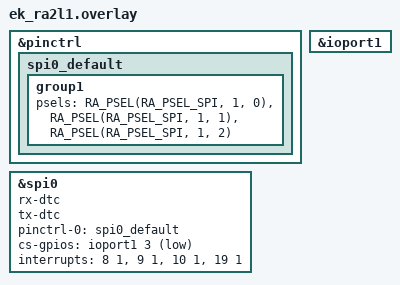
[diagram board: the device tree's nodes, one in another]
/*
 * Copyright (c) 2024 Renesas Electronics Corporation
 * SPDX-License-Identifier: Apache-2.0
 */

#define SPI_LOOPBACK_SLOW_HZ 2000000
#define SPI_LOOPBACK_FAST_HZ 3000000

&pinctrl {
	spi0_default: spi0_default {
		group1 {
			/* MISO MOSI RSPCK */
			psels = <RA_PSEL(RA_PSEL_SPI, 1, 0)>,
				<RA_PSEL(RA_PSEL_SPI, 1, 1)>,
				<RA_PSEL(RA_PSEL_SPI, 1, 2)>;
		};
	};
};

spi_loopback: &spi0 {
	rx-dtc;
	tx-dtc;
	pinctrl-0 = <&spi0_default>;
	pinctrl-names = "default";
	cs-gpios = <&ioport1 3 GPIO_ACTIVE_LOW>;
	interrupts = <8 1>, <9 1>, <10 1>, <19 1>;
	interrupt-names = "rxi", "txi", "tei", "eri";
	status = "okay";
};

&ioport1 {
	status = "okay";
};

#include "../spi-loopback.dtsi"
